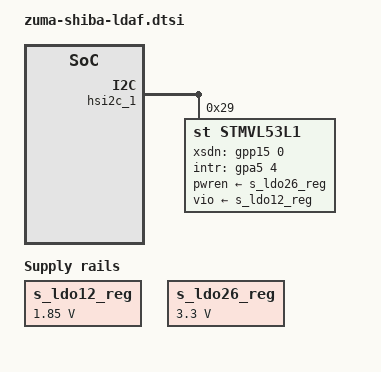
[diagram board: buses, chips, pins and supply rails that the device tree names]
// SPDX-License-Identifier: GPL-2.0-only
/*
 * Shiba ldaf(Laser Detection Auto Focus) device tree source
 *
 * Copyright 2022 Google LLC.
 *
 */

#include <dt-bindings/gpio/gpio.h>

&pinctrl_2 {
	ldaf_irq: ldaf-irq {
		samsung,pins = "gpa5-4"; /* XEINT_4 */
		samsung,pin-function = <EXYNOS_PIN_FUNC_INPUT>;
		samsung,pin-pud = <EXYNOS_PIN_PULL_NONE>;
	};
};

&s_ldo12_reg {
	regulator-min-microvolt = <1850000>;
	regulator-max-microvolt = <1850000>;
};

&s_ldo26_reg {
	regulator-min-microvolt = <3300000>;
	regulator-max-microvolt = <3300000>;
};

&hsi2c_1 {
	status = "ok";
	#address-cells = <1>;
	#size-cells = <0>;
	stmvl53l1: stmvl53l1@29 {
		compatible = "st,stmvl53l1";
		reg = <0x29>;

		/* VADD 3.3V */
		pwren-supply = <&s_ldo26_reg>;

		/* RESET: XAPC_MCLK8: GPP15[0] */
		xsdn-gpio = <&gpp15 0 GPIO_ACTIVE_HIGH>;

		/* IRQ: XEINT_4: GPA5[4] */
		intr-gpio = <&gpa5 4 GPIO_ACTIVE_HIGH>;

		/* IOVDD: 1.8V */
		vio-type = "regulator";
		vio-supply = <&s_ldo12_reg>;
		vio-voltage = <1800000>;

		pinctrl-names = "default";
		pinctrl-0 = <&ldaf_irq>;

		status = "ok";
	};
};
